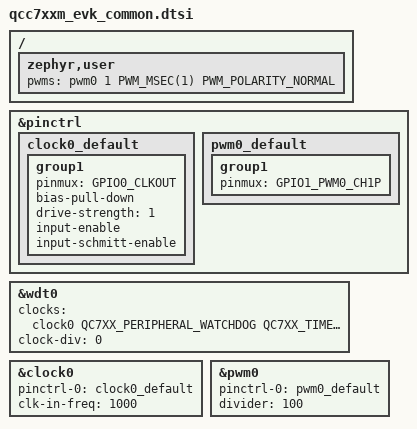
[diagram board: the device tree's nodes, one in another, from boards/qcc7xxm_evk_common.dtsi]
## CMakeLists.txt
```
# Copyright (c) 2026 Qualcomm Technologies, Inc. and/or its subsidiaries
# SPDX-License-Identifier: BSD-3-Clause

cmake_minimum_required(VERSION 3.20.0)
find_package(Zephyr REQUIRED HINTS $ENV{ZEPHYR_BASE})
project(watchdog_gpio_clk_src)

target_sources(app PRIVATE src/main.c)
```

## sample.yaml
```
# Copyright (c) 2026 Qualcomm Technologies, Inc. and/or its subsidiaries
# SPDX-License-Identifier: BSD-3-Clause

sample:
  name: Watchdog driver sample for Opal
common:
  timeout: 120
  harness: console
  harness_config:
    type: multi_line
    ordered: true
    regex:
      - "Watchdog sample application"
      - "Feeding watchdog..."
      - "Waiting for reset..."
      - "Handled things..ready to reset"
      - "Watchdog sample application"
tests:
  qcc7xx.sample.drivers.watchdog_gpio_clk_src:
    platform_allow:
      - qcc744m_evk
      - qcc743m_evk
      - qcc75xm_evk
    extra_configs:
      - CONFIG_REBOOT=y
```

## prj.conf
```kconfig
CONFIG_LOG=y
CONFIG_LOG_MODE_IMMEDIATE=y
CONFIG_WDT_LOG_LEVEL_DBG=y
CONFIG_WATCHDOG=y
CONFIG_WDT_DISABLE_AT_BOOT=n
CONFIG_PWM=y
```

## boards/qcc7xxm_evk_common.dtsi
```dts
/*
 * Copyright (c) 2026 Qualcomm Technologies, Inc. and/or its subsidiaries
 * SPDX-License-Identifier: BSD-3-Clause
 */

/ {
	zephyr,user {
		pwms = <&pwm0 1 PWM_MSEC(1) PWM_POLARITY_NORMAL>;
	};
};

&pinctrl {
	clock0_default: clock0_default {
		group1 {
			pinmux = <GPIO0_CLKOUT>;
			bias-pull-down;
			drive-strength = <1>;
			input-enable;
			input-schmitt-enable;
		};
	};
	
	pwm0_default: pwm0_default {
		group1 {
			pinmux = <GPIO1_PWM0_CH1P>;
		};
	};
};

&wdt0 {
	clocks = <&clock0 QC7XX_PERIPHERAL_WATCHDOG QC7XX_TIMER_CLK_GPIO>;
	status = "okay";
	clock-div = <0>;
};

&clock0 {
	status = "okay";
	pinctrl-0 = <&clock0_default>;
	pinctrl-names = "default";
	clk-in-freq = <1000>;
};

&pwm0 {
	status = "okay";
	pinctrl-0 = <&pwm0_default>;
	divider = <100>;
	pinctrl-names = "default";
};
```

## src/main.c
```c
/*
 * Copyright (c) 2015 Intel Corporation
 * Copyright (c) 2018 Nordic Semiconductor
 * Copyright (c) 2019 Centaur Analytics, Inc
 * Copyright 2023 NXP
 *
 * SPDX-License-Identifier: Apache-2.0
 *
 * Copyright (c) Qualcomm Technologies, Inc. and/or its subsidiaries
 * SPDX-License-Identifier: BSD-3-Clause
 * Not a contribution.
 */

#include <zephyr/kernel.h>
#include <zephyr/device.h>
#include <zephyr/drivers/watchdog.h>
#include <zephyr/sys/printk.h>
#include <stdbool.h>

#define WDT_FEED_TRIES 5

/*
 * To use this sample the devicetree's /aliases must have a 'watchdog0' property.
 */
#ifndef WDT_ALLOW_CALLBACK
#define WDT_ALLOW_CALLBACK 1
#endif

#ifndef WDT_MAX_WINDOW
#define WDT_MAX_WINDOW  1000U
#endif

#ifndef WDT_MIN_WINDOW
#define WDT_MIN_WINDOW  0U
#endif

#ifndef WDG_FEED_INTERVAL
#define WDG_FEED_INTERVAL 50U
#endif

#ifndef WDT_OPT
#define WDT_OPT WDT_OPT_PAUSE_HALTED_BY_DBG
#endif

#if WDT_ALLOW_CALLBACK
static void wdt_callback(const struct device *wdt_dev, int channel_id)
{
	static bool handled_event;

	if (handled_event) {
		return;
	}

	wdt_feed(wdt_dev, channel_id);

	printk("Handled things..ready to reset\n");
	handled_event = true;
}
#endif /* WDT_ALLOW_CALLBACK */

int main(void)
{
	int err;
	int wdt_channel_id;
	const struct device *const wdt = DEVICE_DT_GET(DT_ALIAS(watchdog0));

	printk("Watchdog sample application\n");

	if (!device_is_ready(wdt)) {
		printk("%s: device not ready.\n", wdt->name);
		return 0;
	}

	struct wdt_timeout_cfg wdt_config = {
		/* Reset SoC when watchdog timer expires. */
		.flags = WDT_FLAG_RESET_SOC,

		/* Expire watchdog after max window */
		.window.min = WDT_MIN_WINDOW,
		.window.max = WDT_MAX_WINDOW,
	};

#if WDT_ALLOW_CALLBACK
	/* Set up watchdog callback. */
	wdt_config.callback = wdt_callback;

	printk("Attempting to test pre-reset callback\n");
#else /* WDT_ALLOW_CALLBACK */
	printk("Callback in RESET_SOC disabled for this platform\n");
#endif /* WDT_ALLOW_CALLBACK */

	wdt_channel_id = wdt_install_timeout(wdt, &wdt_config);
	if (wdt_channel_id == -ENOTSUP) {
		/* IWDG driver for STM32 doesn't support callback */
		printk("Callback support rejected, continuing anyway\n");
		wdt_config.callback = NULL;
		wdt_channel_id = wdt_install_timeout(wdt, &wdt_config);
	}
	if (wdt_channel_id < 0) {
		printk("Watchdog install error\n");
		return 0;
	}

	err = wdt_setup(wdt, WDT_OPT);
	if (err < 0) {
		printk("Watchdog setup error\n");
		return 0;
	}

#if WDT_MIN_WINDOW != 0
	/* Wait opening window. */
	k_msleep(WDT_MIN_WINDOW);
#endif
	/* Feeding watchdog. */
	printk("Feeding watchdog %d times\n", WDT_FEED_TRIES);
	for (int i = 0; i < WDT_FEED_TRIES; ++i) {
		printk("Feeding watchdog...\n");
		wdt_feed(wdt, wdt_channel_id);
		k_sleep(K_MSEC(WDG_FEED_INTERVAL));
	}

	/* Waiting for the SoC reset. */
	printk("Waiting for reset...\n");
	while (1) {
		k_yield();
	}
	return 0;
}
```
